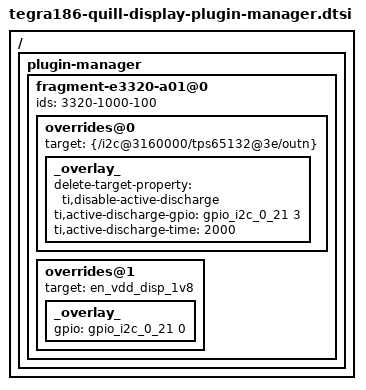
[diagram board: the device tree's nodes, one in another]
/*
 * tegra186-quill-display-plugin-manager.dtsi: Display override DTSI file.
 *
 * Copyright (c) 2015, NVIDIA CORPORATION.  All rights reserved.
 *
 * This program is free software; you can redistribute it and/or modify
 * it under the terms of the GNU General Public License as published by
 * the Free Software Foundation; version 2 of the License.
 *
 * This program is distributed in the hope that it will be useful, but WITHOUT
 * ANY WARRANTY; without even the implied warranty of MERCHANTABILITY or
 * FITNESS FOR A PARTICULAR PURPOSE.  See the GNU General Public License for
 * more details.
 */

/ {
	plugin-manager {
		fragment-e3320-a01@0 {
			ids = "3320-1000-100";
			overrides@0 {
				target = <&{/i2c@3160000/tps65132@3e/outn}>;
				_overlay_ {
					delete-target-property = "ti,disable-active-discharge";
					ti,active-discharge-gpio = <&gpio_i2c_0_21 3 0>;
					ti,active-discharge-time = <2000>; /* in us */
				};
			};
			overrides@1 {
				target = <&en_vdd_disp_1v8>;
				_overlay_ {
					gpio = <&gpio_i2c_0_21 0 0>;
				};
			};
		};
	};
};
